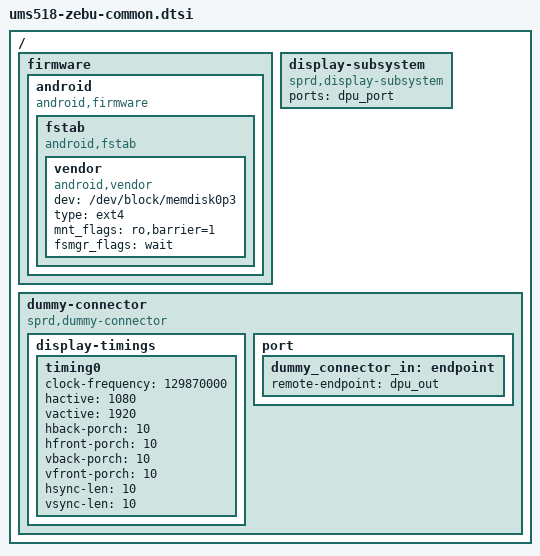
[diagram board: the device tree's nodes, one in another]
/*
 * Spreadtrum Sharkl5Pro board common DTS file
 *
 * Copyright (C) 2018, Spreadtrum Communications Inc.
 *
 * This file is licensed under a dual GPLv2 or X11 license.
 */

#include "lcd/lcd_dummy_mipi.dtsi"

/ {
	firmware {
		android {
			compatible = "android,firmware";

			fstab {
				compatible = "android,fstab";
				vendor {
					compatible = "android,vendor";
					dev = "/dev/block/memdisk0p3";
					type = "ext4";
					mnt_flags = "ro,barrier=1";
					fsmgr_flags = "wait";
				};
			};
		};
	};

	display-subsystem {
		compatible = "sprd,display-subsystem";
		ports = <&dpu_port>;
		/*gsp = <&gsp>;*/
	};

	dummy-connector {
		compatible = "sprd,dummy-connector";

		display-timings {
			timing0 {
				clock-frequency = <129870000>;
				hactive = <1080>;
				vactive = <1920>;
				hback-porch = <10>;
				hfront-porch = <10>;
				vback-porch = <10>;
				vfront-porch = <10>;
				hsync-len = <10>;
				vsync-len = <10>;
			};
		};

		port {
			dummy_connector_in: endpoint {
				remote-endpoint = <&dpu_out>;
			};
		};
	};
};
